VERSION ""

NS_ :

BS_:

BU_: IZZE_WL_SG_42A

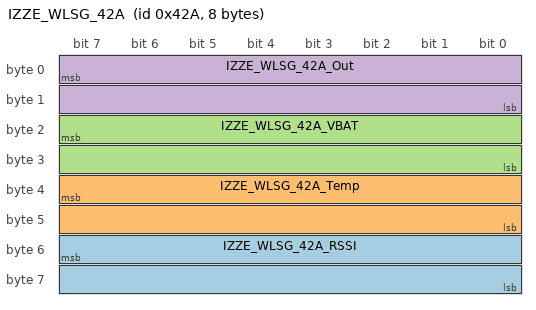
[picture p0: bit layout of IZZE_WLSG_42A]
BO_ 1066 IZZE_WLSG_42A: 8 IZZE_WL_SG_42A
 SG_ IZZE_WLSG_42A_RSSI : 55|16@0- (1,0) [0|0] "dBm" Vector__XXX
 SG_ IZZE_WLSG_42A_Temp : 39|16@0- (0.1,0) [0|0] "C" Vector__XXX
 SG_ IZZE_WLSG_42A_VBAT : 23|16@0- (0.001,0) [0|0] "V" Vector__XXX
 SG_ IZZE_WLSG_42A_Out : 7|16@0- (1,0) [0|0] "uV" Vector__XXX

CM_ BO_ 1066 "Left wireless IZZE - Output, Battery, Temperature, RSSI";
BA_DEF_  "BusType" STRING ;
BA_DEF_DEF_  "BusType" "";
BA_ "BusType" "CAN";
